# PIC32MZ2048EFM144 register map
Registers are 32-bit, access not given, reset 0x0 unless marked. A register's access mark holds for its fields unless they carry their own. Offsets are from the block's base; [hi:lo] are bit positions; {n}, {i} and the like mark numbered series; 'fields as' and 'values as' point back to an identical list.

## PORTE — PORTE peripheral
Base 0xBF860400
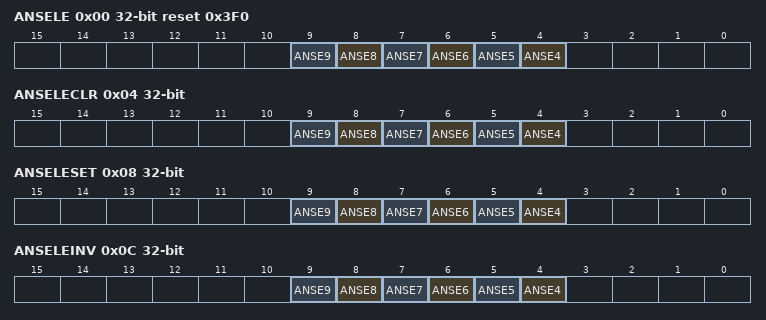
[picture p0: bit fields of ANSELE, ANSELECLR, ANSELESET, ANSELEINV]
0x00 ANSELE reset 0x3F0
  [n] ANSE{n} (n=4..9)
0x04 ANSELECLR
  [n] ANSE{n} (n=4..9)
0x08 ANSELESET
  [n] ANSE{n} (n=4..9)
0x0C ANSELEINV
  [n] ANSE{n} (n=4..9)
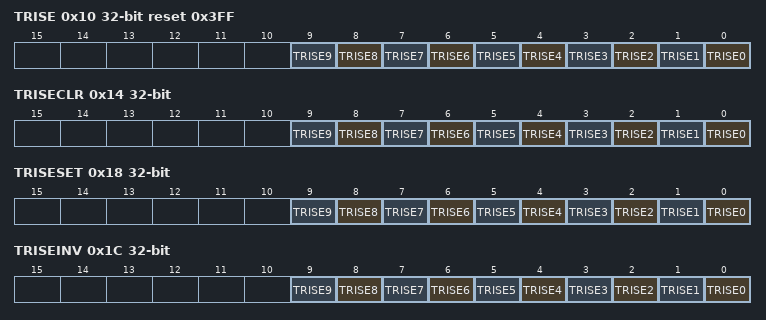
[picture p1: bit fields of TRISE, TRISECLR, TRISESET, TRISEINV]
0x10 TRISE reset 0x3FF
  [n] TRISE{n} (n=0..9)
0x14 TRISECLR
  [n] TRISE{n} (n=0..9)
0x18 TRISESET
  [n] TRISE{n} (n=0..9)
0x1C TRISEINV
  [n] TRISE{n} (n=0..9)
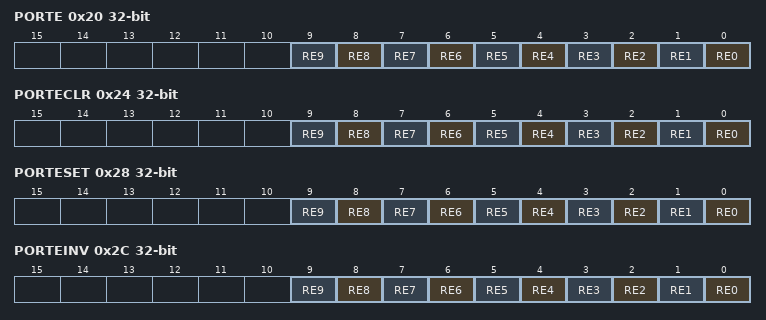
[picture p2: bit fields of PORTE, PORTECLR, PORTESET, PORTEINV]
0x20 PORTE
  [n] RE{n} (n=0..9)
0x24 PORTECLR
  [n] RE{n} (n=0..9)
0x28 PORTESET
  [n] RE{n} (n=0..9)
0x2C PORTEINV
  [n] RE{n} (n=0..9)
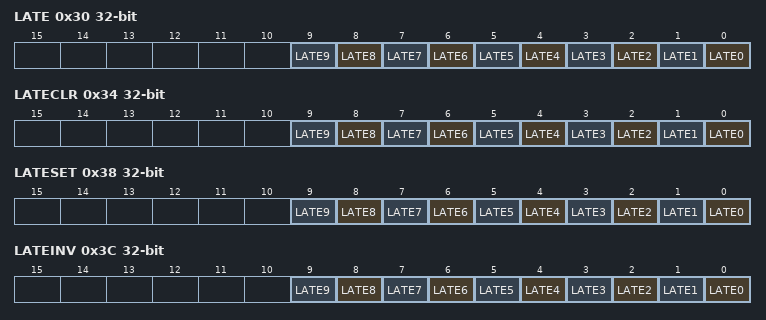
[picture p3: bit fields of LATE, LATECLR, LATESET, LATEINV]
0x30 LATE
  [n] LATE{n} (n=0..9)
0x34 LATECLR
  [n] LATE{n} (n=0..9)
0x38 LATESET
  [n] LATE{n} (n=0..9)
0x3C LATEINV
  [n] LATE{n} (n=0..9)
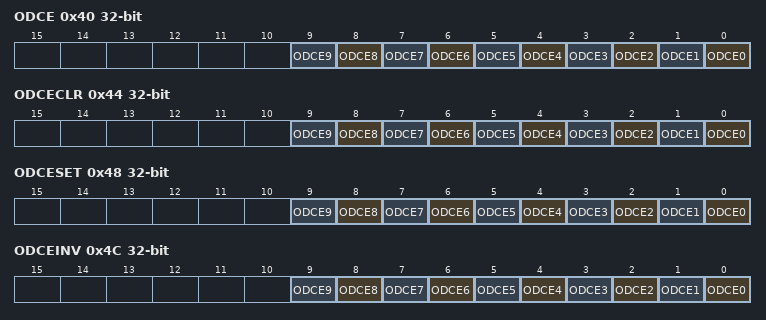
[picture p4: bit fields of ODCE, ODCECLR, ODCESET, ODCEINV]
0x40 ODCE
  [n] ODCE{n} (n=0..9)
0x44 ODCECLR
  [n] ODCE{n} (n=0..9)
0x48 ODCESET
  [n] ODCE{n} (n=0..9)
0x4C ODCEINV
  [n] ODCE{n} (n=0..9)
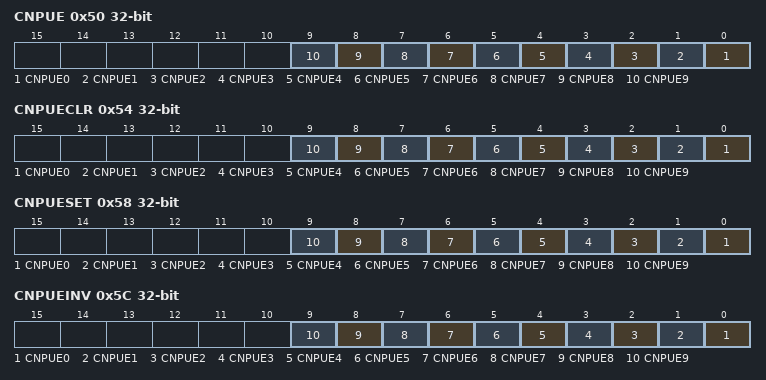
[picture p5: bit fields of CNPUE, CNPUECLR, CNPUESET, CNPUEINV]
0x50 CNPUE
  [n] CNPUE{n} (n=0..9)
0x54 CNPUECLR
  [n] CNPUE{n} (n=0..9)
0x58 CNPUESET
  [n] CNPUE{n} (n=0..9)
0x5C CNPUEINV
  [n] CNPUE{n} (n=0..9)
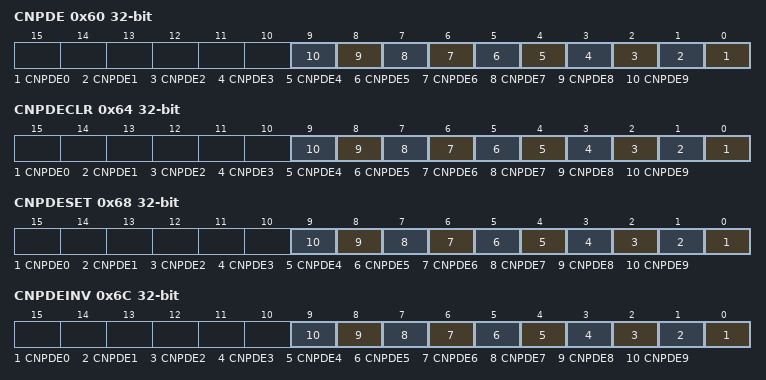
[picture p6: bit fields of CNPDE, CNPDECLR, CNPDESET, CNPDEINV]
0x60 CNPDE
  [n] CNPDE{n} (n=0..9)
0x64 CNPDECLR
  [n] CNPDE{n} (n=0..9)
0x68 CNPDESET
  [n] CNPDE{n} (n=0..9)
0x6C CNPDEINV
  [n] CNPDE{n} (n=0..9)
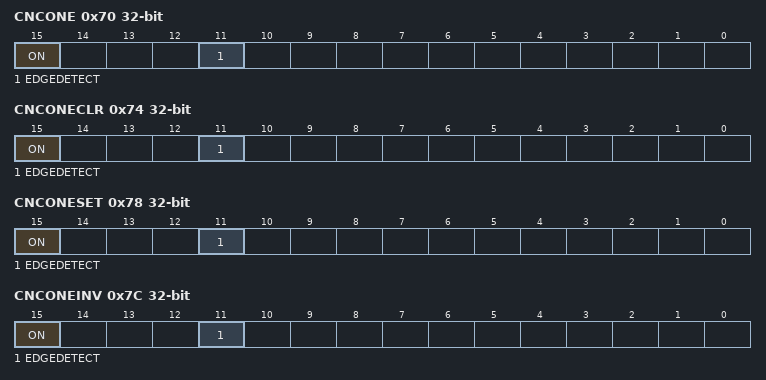
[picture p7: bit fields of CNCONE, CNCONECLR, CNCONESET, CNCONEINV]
0x70 CNCONE
  [15] ON, [11] EDGEDETECT
0x74 CNCONECLR
  [15] ON, [11] EDGEDETECT
0x78 CNCONESET
  [15] ON, [11] EDGEDETECT
0x7C CNCONEINV
  [15] ON, [11] EDGEDETECT
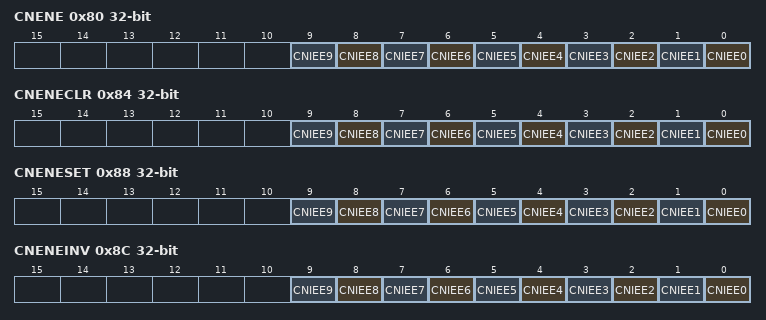
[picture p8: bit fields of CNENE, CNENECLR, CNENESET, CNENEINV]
0x80 CNENE
  [n] CNIEE{n} (n=0..9)
0x84 CNENECLR
  [n] CNIEE{n} (n=0..9)
0x88 CNENESET
  [n] CNIEE{n} (n=0..9)
0x8C CNENEINV
  [n] CNIEE{n} (n=0..9)
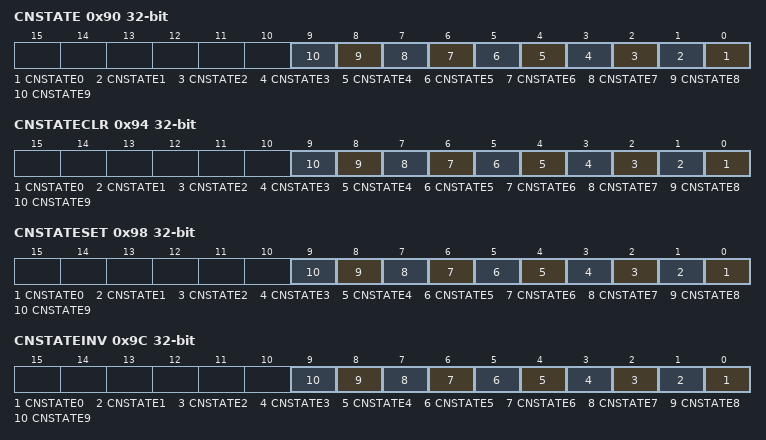
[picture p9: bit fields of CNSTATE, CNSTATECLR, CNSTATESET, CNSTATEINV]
0x90 CNSTATE
  [n] CNSTATE{n} (n=0..9)
0x94 CNSTATECLR
  [n] CNSTATE{n} (n=0..9)
0x98 CNSTATESET
  [n] CNSTATE{n} (n=0..9)
0x9C CNSTATEINV
  [n] CNSTATE{n} (n=0..9)
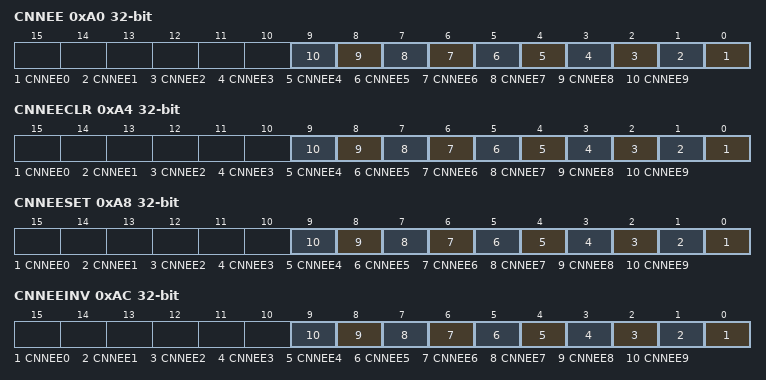
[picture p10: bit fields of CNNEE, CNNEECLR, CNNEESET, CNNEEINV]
0xA0 CNNEE
  [n] CNNEE{n} (n=0..9)
0xA4 CNNEECLR
  [n] CNNEE{n} (n=0..9)
0xA8 CNNEESET
  [n] CNNEE{n} (n=0..9)
0xAC CNNEEINV
  [n] CNNEE{n} (n=0..9)
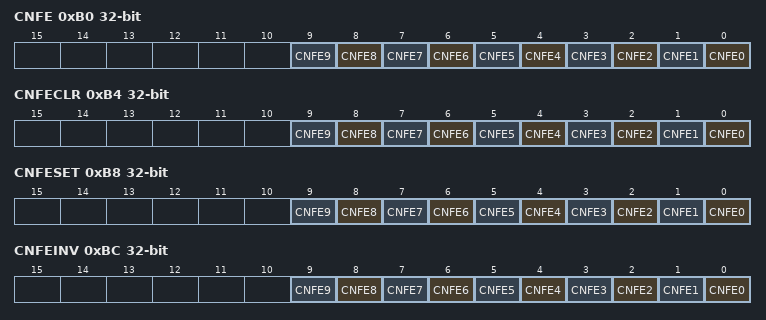
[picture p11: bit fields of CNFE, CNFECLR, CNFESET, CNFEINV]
0xB0 CNFE
  [n] CNFE{n} (n=0..9)
0xB4 CNFECLR
  [n] CNFE{n} (n=0..9)
0xB8 CNFESET
  [n] CNFE{n} (n=0..9)
0xBC CNFEINV
  [n] CNFE{n} (n=0..9)
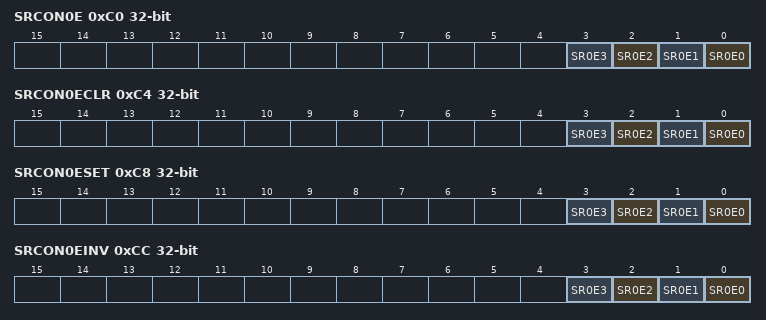
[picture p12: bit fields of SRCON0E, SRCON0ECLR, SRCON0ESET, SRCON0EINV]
0xC0 SRCON0E
  [n] SR0E{n} (n=0..3)
0xC4 SRCON0ECLR
  [n] SR0E{n} (n=0..3)
0xC8 SRCON0ESET
  [n] SR0E{n} (n=0..3)
0xCC SRCON0EINV
  [n] SR0E{n} (n=0..3)
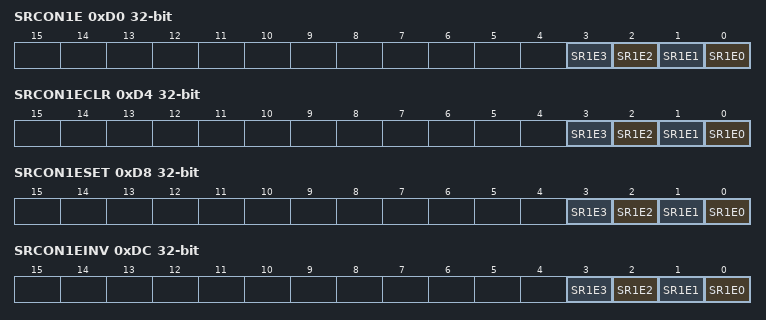
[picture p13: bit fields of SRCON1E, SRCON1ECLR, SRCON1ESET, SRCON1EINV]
0xD0 SRCON1E
  [n] SR1E{n} (n=0..3)
0xD4 SRCON1ECLR
  [n] SR1E{n} (n=0..3)
0xD8 SRCON1ESET
  [n] SR1E{n} (n=0..3)
0xDC SRCON1EINV
  [n] SR1E{n} (n=0..3)

## PORTF — PORTF peripheral
Base 0xBF860500
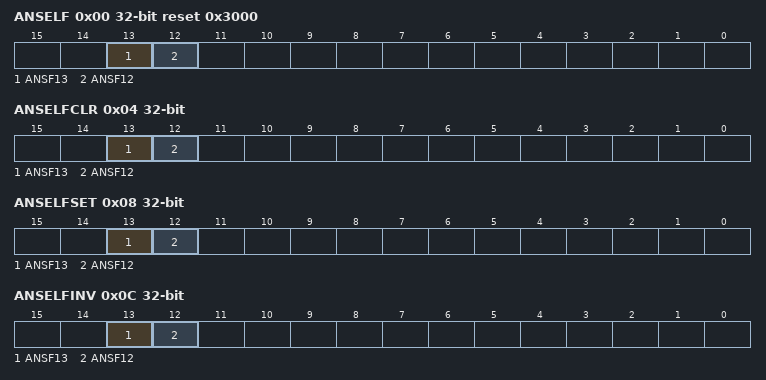
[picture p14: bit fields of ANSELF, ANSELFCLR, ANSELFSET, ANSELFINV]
0x00 ANSELF reset 0x3000
  [13] ANSF13, [12] ANSF12
0x04 ANSELFCLR
  [13] ANSF13, [12] ANSF12
0x08 ANSELFSET
  [13] ANSF13, [12] ANSF12
0x0C ANSELFINV
  [13] ANSF13, [12] ANSF12
0x10 TRISF reset 0x313F
  [13] TRISF13, [12] TRISF12, [8] TRISF8, [n] TRISF{n} (n=0..5)
0x14 TRISFCLR
  [13] TRISF13, [12] TRISF12, [8] TRISF8, [n] TRISF{n} (n=0..5)
0x18 TRISFSET
  [13] TRISF13, [12] TRISF12, [8] TRISF8, [n] TRISF{n} (n=0..5)
0x1C TRISFINV
  [13] TRISF13, [12] TRISF12, [8] TRISF8, [n] TRISF{n} (n=0..5)
0x20 PORTF
  [13] RF13, [12] RF12, [8] RF8, [n] RF{n} (n=0..5)
0x24 PORTFCLR
  [13] RF13, [12] RF12, [8] RF8, [n] RF{n} (n=0..5)
0x28 PORTFSET
  [13] RF13, [12] RF12, [8] RF8, [n] RF{n} (n=0..5)
0x2C PORTFINV
  [13] RF13, [12] RF12, [8] RF8, [n] RF{n} (n=0..5)
0x30 LATF
  [13] LATF13, [12] LATF12, [8] LATF8, [n] LATF{n} (n=0..5)
0x34 LATFCLR
  [13] LATF13, [12] LATF12, [8] LATF8, [n] LATF{n} (n=0..5)
0x38 LATFSET
  [13] LATF13, [12] LATF12, [8] LATF8, [n] LATF{n} (n=0..5)
0x3C LATFINV
  [13] LATF13, [12] LATF12, [8] LATF8, [n] LATF{n} (n=0..5)
0x40 ODCF
  [13] ODCF13, [12] ODCF12, [8] ODCF8, [n] ODCF{n} (n=0..5)
0x44 ODCFCLR
  [13] ODCF13, [12] ODCF12, [8] ODCF8, [n] ODCF{n} (n=0..5)
0x48 ODCFSET
  [13] ODCF13, [12] ODCF12, [8] ODCF8, [n] ODCF{n} (n=0..5)
0x4C ODCFINV
  [13] ODCF13, [12] ODCF12, [8] ODCF8, [n] ODCF{n} (n=0..5)
0x50 CNPUF
  [13] CNPUF13, [12] CNPUF12, [8] CNPUF8, [n] CNPUF{n} (n=0..5)
0x54 CNPUFCLR
  [13] CNPUF13, [12] CNPUF12, [8] CNPUF8, [n] CNPUF{n} (n=0..5)
0x58 CNPUFSET
  [13] CNPUF13, [12] CNPUF12, [8] CNPUF8, [n] CNPUF{n} (n=0..5)
0x5C CNPUFINV
  [13] CNPUF13, [12] CNPUF12, [8] CNPUF8, [n] CNPUF{n} (n=0..5)
0x60 CNPDF
  [13] CNPDF13, [12] CNPDF12, [8] CNPDF8, [n] CNPDF{n} (n=0..5)
0x64 CNPDFCLR
  [13] CNPDF13, [12] CNPDF12, [8] CNPDF8, [n] CNPDF{n} (n=0..5)
0x68 CNPDFSET
  [13] CNPDF13, [12] CNPDF12, [8] CNPDF8, [n] CNPDF{n} (n=0..5)
0x6C CNPDFINV
  [13] CNPDF13, [12] CNPDF12, [8] CNPDF8, [n] CNPDF{n} (n=0..5)
0x70 CNCONF
  [15] ON, [11] EDGEDETECT
0x74 CNCONFCLR
  [15] ON, [11] EDGEDETECT
0x78 CNCONFSET
  [15] ON, [11] EDGEDETECT
0x7C CNCONFINV
  [15] ON, [11] EDGEDETECT
0x80 CNENF
  [13] CNIEF13, [12] CNIEF12, [8] CNIEF8, [n] CNIEF{n} (n=0..5)
0x84 CNENFCLR
  [13] CNIEF13, [12] CNIEF12, [8] CNIEF8, [n] CNIEF{n} (n=0..5)
0x88 CNENFSET
  [13] CNIEF13, [12] CNIEF12, [8] CNIEF8, [n] CNIEF{n} (n=0..5)
0x8C CNENFINV
  [13] CNIEF13, [12] CNIEF12, [8] CNIEF8, [n] CNIEF{n} (n=0..5)
0x90 CNSTATF
  [13] CNSTATF13, [12] CNSTATF12, [8] CNSTATF8, [n] CNSTATF{n} (n=0..5)
0x94 CNSTATFCLR
  fields as CNSTATF
0x98 CNSTATFSET
  fields as CNSTATF
0x9C CNSTATFINV
  fields as CNSTATF
0xA0 CNNEF
  [13] CNNEF13, [12] CNNEF12, [8] CNNEF8, [n] CNNEF{n} (n=0..5)
0xA4 CNNEFCLR
  [13] CNNEF13, [12] CNNEF12, [8] CNNEF8, [n] CNNEF{n} (n=0..5)
0xA8 CNNEFSET
  [13] CNNEF13, [12] CNNEF12, [8] CNNEF8, [n] CNNEF{n} (n=0..5)
0xAC CNNEFINV
  [13] CNNEF13, [12] CNNEF12, [8] CNNEF8, [n] CNNEF{n} (n=0..5)
0xB0 CNFF
  [13] CNFF13, [12] CNFF12, [8] CNFF8, [n] CNFF{n} (n=0..5)
0xB4 CNFFCLR
  [13] CNFF13, [12] CNFF12, [8] CNFF8, [n] CNFF{n} (n=0..5)
0xB8 CNFFSET
  [13] CNFF13, [12] CNFF12, [8] CNFF8, [n] CNFF{n} (n=0..5)
0xBC CNFFINV
  [13] CNFF13, [12] CNFF12, [8] CNFF8, [n] CNFF{n} (n=0..5)
0xC0 SRCON0F
  [1] SR0F1, [0] SR0F0
0xC4 SRCON0FCLR
  [1] SR0F1, [0] SR0F0
0xC8 SRCON0FSET
  [1] SR0F1, [0] SR0F0
0xCC SRCON0FINV
  [1] SR0F1, [0] SR0F0
0xD0 SRCON1F
  [1] SR1F1, [0] SR1F0
0xD4 SRCON1FCLR
  [1] SR1F1, [0] SR1F0
0xD8 SRCON1FSET
  [1] SR1F1, [0] SR1F0
0xDC SRCON1FINV
  [1] SR1F1, [0] SR1F0
